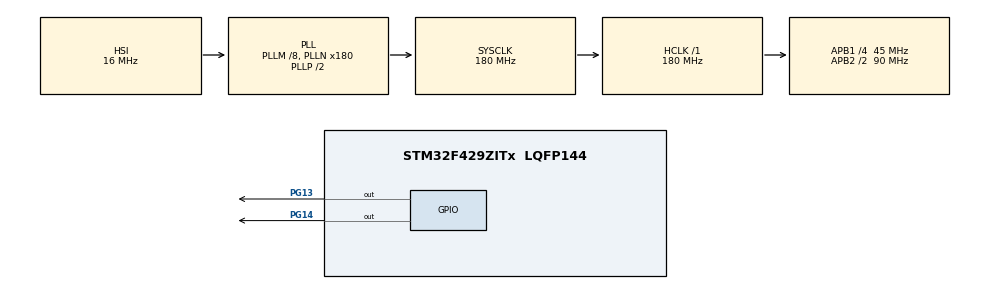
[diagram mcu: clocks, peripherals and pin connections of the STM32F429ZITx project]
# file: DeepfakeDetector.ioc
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Mcu.Family=STM32F4
Mcu.Name=STM32F429ZITx
Mcu.Package=LQFP144
NVIC.PriorityGroup=NVIC_PRIORITYGROUP_4
PG13.Signal=GPIO_Output
PG14.Signal=GPIO_Output
ProjectManager.HeapSize=0x200
ProjectManager.StackSize=0x400
ProjectManager.TargetToolchain=STM32CubeIDE
RCC.48MHZClocksFreq_Value=90000000
RCC.AHBFreq_Value=180000000
RCC.APB1CLKDivider=RCC_HCLK_DIV4
RCC.APB1Freq_Value=45000000
RCC.APB1TimFreq_Value=90000000
RCC.APB2CLKDivider=RCC_HCLK_DIV2
RCC.APB2Freq_Value=90000000
RCC.APB2TimFreq_Value=180000000
RCC.CortexFreq_Value=180000000
RCC.HCLKFreq_Value=180000000
RCC.HSE_VALUE=25000000
RCC.HSI_VALUE=16000000
RCC.LSE_VALUE=32768
RCC.PLLM=8
RCC.PLLN=180
RCC.SYSCLKFreq_VALUE=180000000
RCC.SYSCLKSource=RCC_SYSCLKSOURCE_PLLCLK
RCC.VCOOutputFreq_Value=360000000
STMicroelectronics.X-CUBE-AI.10.0.0.ActivationBufferSizeList=109888
STMicroelectronics.X-CUBE-AI.10.0.0.ActivationBuffers=pool0
STMicroelectronics.X-CUBE-AI.10.0.0.ActivationNames=pool0
STMicroelectronics.X-CUBE-AI.10.0.0.ActivationSizes=AI_NETWORK_DATA_ACTIVATION_1_SIZE
STMicroelectronics.X-CUBE-AI.10.0.0.HeapSize=0x800
STMicroelectronics.X-CUBE-AI.10.0.0.InternalRamActivationBufferMaxSize=AI_NETWORK_DATA_ACTIVATIONS_SIZE
STMicroelectronics.X-CUBE-AI.10.0.0.LatestDirectoryUsed-4f0120a31d0c93de716ce8fcf4858711c85b00eac5f2bbc83abbeb1bac8d87c9=C\:\\OM\\8 Embedded Systems
STMicroelectronics.X-CUBE-AI.10.0.0.MaximumNumberOfInputLayer=1
STMicroelectronics.X-CUBE-AI.10.0.0.MaximumNumberOfOutputLayer=1
STMicroelectronics.X-CUBE-AI.10.0.0.MaximumSizeOfInputLayer=1
STMicroelectronics.X-CUBE-AI.10.0.0.MaximumSizeOfOutputLayer=1
STMicroelectronics.X-CUBE-AI.10.0.0.ModelActualCompression-4f0120a31d0c93de716ce8fcf4858711c85b00eac5f2bbc83abbeb1bac8d87c9=0.0
STMicroelectronics.X-CUBE-AI.10.0.0.ModelCompression-4f0120a31d0c93de716ce8fcf4858711c85b00eac5f2bbc83abbeb1bac8d87c9=None
STMicroelectronics.X-CUBE-AI.10.0.0.ModelFlashOccupation-4f0120a31d0c93de716ce8fcf4858711c85b00eac5f2bbc83abbeb1bac8d87c9=26436
STMicroelectronics.X-CUBE-AI.10.0.0.ModelHashList=4f0120a31d0c93de716ce8fcf4858711c85b00eac5f2bbc83abbeb1bac8d87c9
STMicroelectronics.X-CUBE-AI.10.0.0.ModelKind-4f0120a31d0c93de716ce8fcf4858711c85b00eac5f2bbc83abbeb1bac8d87c9=TFLITE
STMicroelectronics.X-CUBE-AI.10.0.0.ModelMacc-4f0120a31d0c93de716ce8fcf4858711c85b00eac5f2bbc83abbeb1bac8d87c9=1110396
STMicroelectronics.X-CUBE-AI.10.0.0.ModelName-4f0120a31d0c93de716ce8fcf4858711c85b00eac5f2bbc83abbeb1bac8d87c9=network
STMicroelectronics.X-CUBE-AI.10.0.0.ModelNameList=network
STMicroelectronics.X-CUBE-AI.10.0.0.ModelRamOccupation-4f0120a31d0c93de716ce8fcf4858711c85b00eac5f2bbc83abbeb1bac8d87c9=109888
STMicroelectronics.X-CUBE-AI.10.0.0.ModelStructureFile-4f0120a31d0c93de716ce8fcf4858711c85b00eac5f2bbc83abbeb1bac8d87c9=C\:\\OM\\8 Embedded Systems\\student_model_tiny.tflite
STMicroelectronics.X-CUBE-AI.10.0.0.ModelType-4f0120a31d0c93de716ce8fcf4858711c85b00eac5f2bbc83abbeb1bac8d87c9=STM32Cube.AI MCU runtime
STMicroelectronics.X-CUBE-AI.10.0.0.ReadyForCodeGeneration=true
STMicroelectronics.X-CUBE-AI.10.0.0.StackSize=0x800
STMicroelectronics.X-CUBE-AI.10.0.0.WorkingBufferStartAddrList=0xFFFFFFFF
STMicroelectronics.X-CUBE-AI.10.0.0.XAaCUBEAaAICcArtificialOoIntelligenceJjCore=true
STMicroelectronics.X-CUBE-AI.10.0.0.copyWeightToRam=false
STMicroelectronics.X-CUBE-AI.10.0.0.customLayerConfigEnabled=false
STMicroelectronics.X-CUBE-AI.10.0.0.noOnnxIoTranspose=false
STMicroelectronics.X-CUBE-AI.10.0.0.useInputAllocation=true
STMicroelectronics.X-CUBE-AI.10.0.0.useOutputAllocation=true
VP_CRC_VS_CRC.Mode=CRC_Activate
VP_STMicroelectronics.X-CUBE-AI_VS_ArtificialOoIntelligenceJjXAaCUBEAaAI_10.0.0.Mode=ArtificialOoIntelligenceJjXAaCUBEAaAI
board=custom

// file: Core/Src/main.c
/* USER CODE BEGIN Header */
/**
  ******************************************************************************
  * @file           : main.c
  * @brief          : Main program body
  ******************************************************************************
  * @attention
  *
  * Copyright (c) 2025 STMicroelectronics.
  * All rights reserved.
  *
  * This software is licensed under terms that can be found in the LICENSE file
  * in the root directory of this software component.
  * If no LICENSE file comes with this software, it is provided AS-IS.
  *
  ******************************************************************************
  */
/* USER CODE END Header */
#include "main.h"
/* USER CODE BEGIN Includes */
#include "network.h"
#include "network_data.h"
#include "image_data.h"
#include <string.h>
#include "ai_platform.h"
#include <sys/stat.h>
#include <stdlib.h>
#include <errno.h>
#include <stdio.h>
#include <signal.h>
#include <time.h>
#include <sys/time.h>
#include <sys/times.h>
#include <string.h>
#include "ai_datatypes_defines.h"

int _close(int file) { return -1; }
int _fstat(int file, struct stat *st) { st->st_mode = S_IFCHR; return 0; }
int _getpid(void) { return 1; }
int _isatty(int file) { return 1; }
int _kill(int pid, int sig) { errno = EINVAL; return -1; }
int _lseek(int file, int ptr, int dir) { return 0; }
int _read(int file, char *ptr, int len) { return 0; }
int _write(int file, char *ptr, int len) { return len; }
/* USER CODE END Includes */

CRC_HandleTypeDef hcrc;

/* USER CODE BEGIN PV */
#define NUM_IMAGES 12
#define IMG_SIZE 12288  // 64x64x3
extern const uint8_t image_0[IMG_SIZE];
extern const uint8_t image_1[IMG_SIZE];
extern const uint8_t image_2[IMG_SIZE];
extern const uint8_t image_3[IMG_SIZE];
extern const uint8_t image_4[IMG_SIZE];
extern const uint8_t image_5[IMG_SIZE];
extern const uint8_t image_6[IMG_SIZE];
extern const uint8_t image_7[IMG_SIZE];
extern const uint8_t image_8[IMG_SIZE];
extern const uint8_t image_9[IMG_SIZE];
extern const uint8_t image_10[IMG_SIZE];
extern const uint8_t image_11[IMG_SIZE];

const uint8_t* images[NUM_IMAGES] = {
  image_0, image_1, image_2, image_3, image_4,
  image_5, image_6, image_7, image_8, image_9,
  image_10, image_11
};

AI_ALIGNED(4) ai_u8 activations[AI_NETWORK_DATA_ACTIVATIONS_SIZE];
AI_ALIGNED(4) float input_data[IMG_SIZE];
AI_ALIGNED(4) float output_data[2];

static ai_handle network = AI_HANDLE_NULL;
static ai_buffer *ai_input;
static ai_buffer *ai_output;
/* USER CODE END PV */

void SystemClock_Config(void);
static void MX_GPIO_Init(void);
static void MX_CRC_Init(void);

int main(void)
{

  /* MCU Configuration--------------------------------------------------------*/

  /* Reset of all peripherals, Initializes the Flash interface and the Systick. */
  HAL_Init();

  /* Configure the system clock */
  SystemClock_Config();

  /* Initialize all configured peripherals */
  MX_GPIO_Init();
  MX_CRC_Init();
  /* USER CODE BEGIN 2 */
  // Initialize AI
  ai_error err;
//  const ai_handle acts[] = { activations };
  err = ai_network_create(&network, AI_NETWORK_DATA_CONFIG);
  if (err.type != AI_ERROR_NONE) {
    Error_Handler();
  }

  // Use the proper initialization macro for parameters
  const ai_network_params params = AI_NETWORK_PARAMS_INIT(
    AI_NETWORK_DATA_WEIGHTS(ai_network_data_weights_get()),
    AI_NETWORK_DATA_ACTIVATIONS(activations)
  );

  if (!ai_network_init(network, &params)) {
    Error_Handler();
  }

//  if (!ai_network_init(network, acts)) {
//    Error_Handler();
//  }

  ai_input = ai_network_inputs_get(network, NULL);
  ai_output = ai_network_outputs_get(network, NULL);

  while (1)
  {
    for (int img_idx = 0; img_idx < NUM_IMAGES; ++img_idx)
    {
      const uint8_t* raw = images[img_idx];
      float mean[3] = {0.485f, 0.456f, 0.406f};
      float std[3] = {0.229f, 0.224f, 0.225f};
//      for (int i = 0; i < IMG_SIZE; ++i)
//        input_data[i] = raw[i] / 255.0f;
      int idx = 0;
      for (int c = 0; c < 3; ++c) {
        for (int h = 0; h < 64; ++h) {
          for (int w = 0; w < 64; ++w) {
            int hwc_index = h * 64 * 3 + w * 3 + c;  // HWC format in raw data
            input_data[idx++] = (raw[hwc_index] / 255.0f - mean[c]) / std[c]; // Converting to [0-1], then apply mean/std normalization
          }
        }
      }

      ai_input[0].data = input_data;
      ai_output[0].data = output_data;
      ai_i32 batch;
      batch = ai_network_run(network, ai_input, ai_output);
      if (batch != 1) {
        Error_Handler();
      }

      float fake = output_data[0];
      float real = output_data[1];

      if (real > fake) {
        HAL_GPIO_WritePin(GPIOG, GPIO_PIN_13, GPIO_PIN_SET);  // Green on
        HAL_GPIO_WritePin(GPIOG, GPIO_PIN_14, GPIO_PIN_RESET);
      } else {
        HAL_GPIO_WritePin(GPIOG, GPIO_PIN_14, GPIO_PIN_SET);  // Red on
        HAL_GPIO_WritePin(GPIOG, GPIO_PIN_13, GPIO_PIN_RESET);
      }

      HAL_Delay(500); // Show result for 1s
      HAL_GPIO_WritePin(GPIOG, GPIO_PIN_14, GPIO_PIN_RESET);
      HAL_GPIO_WritePin(GPIOG, GPIO_PIN_13, GPIO_PIN_RESET);
      HAL_Delay(500);
    }
    break;
    HAL_GPIO_WritePin(GPIOG, GPIO_PIN_13, GPIO_PIN_RESET);
    HAL_GPIO_WritePin(GPIOG, GPIO_PIN_14, GPIO_PIN_RESET);
  }
  /* USER CODE END 2 */

  /* Infinite loop */
  /* USER CODE BEGIN WHILE */
//  while (1)
//  {
//    /* USER CODE END WHILE */
//
//    /* USER CODE BEGIN 3 */
//  }
  /* USER CODE END 3 */
}

void SystemClock_Config(void)
{
  RCC_OscInitTypeDef RCC_OscInitStruct = {0};
  RCC_ClkInitTypeDef RCC_ClkInitStruct = {0};

  /** Configure the main internal regulator output voltage
  */
  __HAL_RCC_PWR_CLK_ENABLE();
  __HAL_PWR_VOLTAGESCALING_CONFIG(PWR_REGULATOR_VOLTAGE_SCALE1);

  /** Initializes the RCC Oscillators according to the specified parameters
  * in the RCC_OscInitTypeDef structure.
  */
  RCC_OscInitStruct.OscillatorType = RCC_OSCILLATORTYPE_HSI;
  RCC_OscInitStruct.HSIState = RCC_HSI_ON;
  RCC_OscInitStruct.HSICalibrationValue = RCC_HSICALIBRATION_DEFAULT;
  RCC_OscInitStruct.PLL.PLLState = RCC_PLL_ON;
  RCC_OscInitStruct.PLL.PLLSource = RCC_PLLSOURCE_HSI;
  RCC_OscInitStruct.PLL.PLLM = 8;
  RCC_OscInitStruct.PLL.PLLN = 180;
  RCC_OscInitStruct.PLL.PLLP = RCC_PLLP_DIV2;
  RCC_OscInitStruct.PLL.PLLQ = 4;
  if (HAL_RCC_OscConfig(&RCC_OscInitStruct) != HAL_OK)
  {
    Error_Handler();
  }

  /** Activate the Over-Drive mode
  */
  if (HAL_PWREx_EnableOverDrive() != HAL_OK)
  {
    Error_Handler();
  }

  /** Initializes the CPU, AHB and APB buses clocks
  */
  RCC_ClkInitStruct.ClockType = RCC_CLOCKTYPE_HCLK|RCC_CLOCKTYPE_SYSCLK
                              |RCC_CLOCKTYPE_PCLK1|RCC_CLOCKTYPE_PCLK2;
  RCC_ClkInitStruct.SYSCLKSource = RCC_SYSCLKSOURCE_PLLCLK;
  RCC_ClkInitStruct.AHBCLKDivider = RCC_SYSCLK_DIV1;
  RCC_ClkInitStruct.APB1CLKDivider = RCC_HCLK_DIV4;
  RCC_ClkInitStruct.APB2CLKDivider = RCC_HCLK_DIV2;

  if (HAL_RCC_ClockConfig(&RCC_ClkInitStruct, FLASH_LATENCY_5) != HAL_OK)
  {
    Error_Handler();
  }
}

static void MX_CRC_Init(void)
{

  hcrc.Instance = CRC;
  if (HAL_CRC_Init(&hcrc) != HAL_OK)
  {
    Error_Handler();
  }

}

static void MX_GPIO_Init(void)
{
  GPIO_InitTypeDef GPIO_InitStruct = {0};

  /* GPIO Ports Clock Enable */
  __HAL_RCC_GPIOG_CLK_ENABLE();

  /*Configure GPIO pin Output Level */
  HAL_GPIO_WritePin(GPIOG, GPIO_PIN_13|GPIO_PIN_14, GPIO_PIN_RESET);

  /*Configure GPIO pins : PG13 PG14 */
  GPIO_InitStruct.Pin = GPIO_PIN_13|GPIO_PIN_14;
  GPIO_InitStruct.Mode = GPIO_MODE_OUTPUT_PP;
  GPIO_InitStruct.Pull = GPIO_NOPULL;
  GPIO_InitStruct.Speed = GPIO_SPEED_FREQ_LOW;
  HAL_GPIO_Init(GPIOG, &GPIO_InitStruct);

}

void blink_(int num){
	for(int i=0;i<num;i++){
		HAL_GPIO_WritePin(GPIOG, GPIO_PIN_14, GPIO_PIN_SET);
		HAL_Delay(500);
		HAL_GPIO_WritePin(GPIOG, GPIO_PIN_14, GPIO_PIN_RESET);
		HAL_Delay(500);
	}
}
void Error_Handler(void)
{
  __disable_irq();
  while (1)
  {
  }
}
